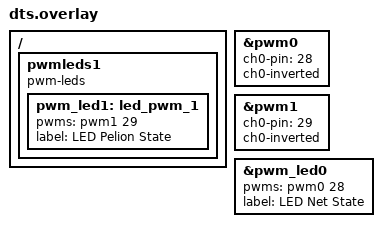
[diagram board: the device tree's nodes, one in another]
/* Copyright (c) 2021 Nordic Semiconductor ASA
 *
 * SPDX-License-Identifier: LicenseRef-Nordic-5-Clause
 */

/ {
	pwmleds1 {
		compatible = "pwm-leds";
		status = "okay";

		pwm_led1: led_pwm_1 {
			pwms = <&pwm1 29>;
			label = "LED Pelion State";
		};
	};
};

&pwm0 {
	status = "okay";
	ch0-pin = <28>;
	ch0-inverted;
};

&pwm1 {
	status = "okay";
	ch0-pin = <29>;
	ch0-inverted;
};

&pwm_led0 {
	status = "okay";
	pwms = <&pwm0 28>;
	label = "LED Net State";
};
